# ESP32-C5 register map
Vendor: ESPRESSIF SYSTEMS (SHANGHAI) CO., LTD.; Series: ESP32 C-Series; File version: 1
CPU: RV32IMAC r0p0, little endian, no MPU, no FPU, 0 interrupt priority bits
Address unit: 32 bits
Registers are 32-bit, read-write, reset 0x0 unless marked. A register's access mark holds for its fields unless they carry their own. Offsets are from the block's base; [hi:lo] are bit positions; {n}, {i} and the like mark numbered series.

## IO_MUX — Input/Output Multiplexer
Base 0x60090000
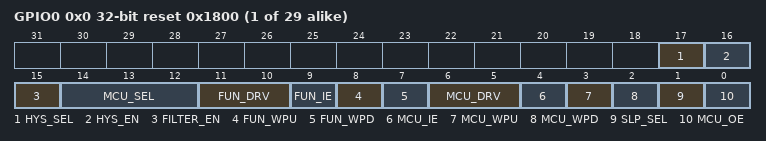
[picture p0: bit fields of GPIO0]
{0x0+4i} GPIO{i} (i=0..28) reset 0x1800 — IO MUX configuration register for GPIO{i}
  [17] HYS_SEL — Configures to choose the signal for enabling the hysteresis function for GPIO%s. \\ 0: Choose the output enable signal of eFuse\\ 1: Choose the output enable signal of IO_MUX_GPIO%s_HYS_EN\\
  [16] HYS_EN — Configures whether or not to enable the hysteresis function of the pin when IO_MUX_GPIO%s_HYS_SEL is set to 1.\\ 0: Disable\\ 1: Enable\\
  [15] FILTER_EN — Configures whether or not to enable filter for pin input signals.\\ 0: Disable\\ 1: Enable\\
  [14:12] MCU_SEL — Configures to select IO MUX function for this signal. \\ 0: Select Function 0\\ 1: Select Function 1\\ ......\\
  [11:10] FUN_DRV — Configures the drive strength of GPIO%s. \\ 0: ~5 mA\\ 1: ~10 mA\\ 2: ~20 mA\\ 3: ~40 mA\\
  [9] FUN_IE — Configures whether or not to enable input of GPIO%s.\\ 0: Disable\\ 1: Enable\\
  [8] FUN_WPU — Configures whether or not enable pull-up resistor of GPIO%s.\\ 0: Disable\\ 1: Enable\\
  [7] FUN_WPD — Configures whether or not to enable pull-down resistor of GPIO%s.\\ 0: Disable\\ 1: Enable\\
  [6:5] MCU_DRV — Configures the drive strength of GPIO%s during sleep mode. \\ 0: ~5 mA\\ 1: ~10 mA\\ 2: ~20 mA\\ 3: ~40 mA\\
  [4] MCU_IE — Configures whether or not to enable the input of GPIO%s during sleep mode.\\ 0: Disable\\ 1: Enable\\
  [3] MCU_WPU — Configures whether or not to enable pull-up resistor of GPIO%s during sleep mode. \\ 0: Disable\\ 1: Enable\\
  [2] MCU_WPD — Configure whether or not to enable pull-down resistor of GPIO%s in sleep mode.\\ 0: Disable\\ 1: Enable\\
  [1] SLP_SEL — Configures whether or not to enter sleep mode for GPIO%s.\\ 0: Not enter\\ 1: Enter\\
  [0] MCU_OE — Configures whether or not to enable the output of GPIO%s in sleep mode. 0: Disable\\ 1: Enable\\
0x1FC DATE — Version control register

## LP_ANA — LP_ANA Peripheral
Base 0x600B2C00
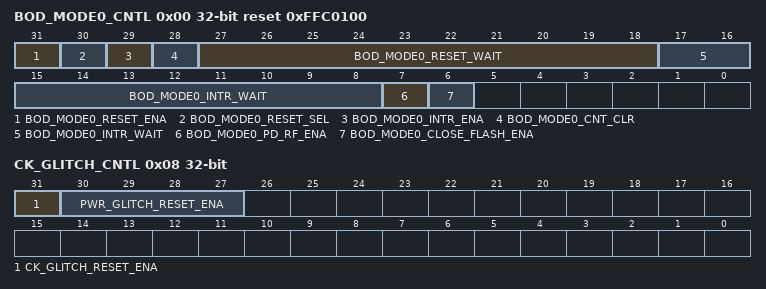
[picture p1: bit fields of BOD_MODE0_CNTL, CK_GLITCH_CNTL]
0x00 BOD_MODE0_CNTL reset 0xFFC0100 — Configure brownout mode0
  [31] BOD_MODE0_RESET_ENA — enable brownout reset or not 1: enable 0: disable
  [30] BOD_MODE0_RESET_SEL — select brownout reset level 1: system reset 0: chip reset
  [29] BOD_MODE0_INTR_ENA — enable brownout interrupt or not 1: enable 0: disable
  [28] BOD_MODE0_CNT_CLR — clear brownout count or not 1: clear 0: no operation
  [27:18] BOD_MODE0_RESET_WAIT — set the undervoltage hold time for triggering brownout reset
  [17:8] BOD_MODE0_INTR_WAIT — set the undervoltage hold time for triggering brownout interrupt
  [7] BOD_MODE0_PD_RF_ENA — enable power down RF when brownout interrupt or not 1:enable 0:disable
  [6] BOD_MODE0_CLOSE_FLASH_ENA — enable suspend spi when brownout interrupt or not 1:enable 0:disable
0x04 BOD_MODE1_CNTL — Configure brownout mode1
  [31] BOD_MODE1_RESET_ENA — enable brownout mode1 reset or not 1: enable 0: disable
0x08 CK_GLITCH_CNTL — Configure power glitch
  [31] CK_GLITCH_RESET_ENA — reserved
  [30:27] PWR_GLITCH_RESET_ENA — enable powerglitch or not
0x0C FIB_ENABLE reset 0xFFFFFFFF — configure FIB REG
  [31:0] ANA_FIB_ENA — configure analog fib by software
0x10 INT_RAW — interrpt raw register
  [31] BOD_MODE0_INT_RAW — brownout mode0 interrupt raw register
0x14 INT_ST ro — interrpt status register
  [31] BOD_MODE0_INT_ST — brownout mode0 interrupt status register
0x18 INT_ENA — interrpt enable register
  [31] BOD_MODE0_INT_ENA — brownout mode0 interrupt enable register
0x1C INT_CLR wo — interrpt clear register
  [31] BOD_MODE0_INT_CLR — brownout mode0 interrupt clear register
0x20 LP_INT_RAW — lp interrupt raw register
  [31] BOD_MODE0_LP_INT_RAW — brownout mode0 lp interrupt raw register
0x24 LP_INT_ST ro — lp interrupt status register
  [31] BOD_MODE0_LP_INT_ST — brownout mode0 lp interrupt status register
0x28 LP_INT_ENA — lp interrupt enable register
  [31] BOD_MODE0_LP_INT_ENA — brownout mode0 lp interrupt enable register
0x2C LP_INT_CLR wo — lp interrupt clear register
  [31] BOD_MODE0_LP_INT_CLR — brownout mode0 lp interrupt clear register
0x3FC DATE — version register
